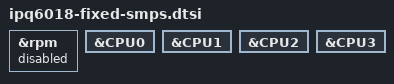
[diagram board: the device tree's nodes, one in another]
// SPDX-License-Identifier: GPL-2.0-or-later OR MIT

&rpm {
	status = "disabled";
};

&CPU0 {
	/delete-property/ cpu-supply;
};

&CPU1 {
	/delete-property/ cpu-supply;
};

&CPU2 {
	/delete-property/ cpu-supply;
};

&CPU3 {
	/delete-property/ cpu-supply;
};
